# LPC54114_cm0plus register map
Vendor: nxp.com; File version: 1.0
CPU: CM0PLUS r0p0, little endian, no MPU, no FPU, VTOR, 2 interrupt priority bits
Registers are 32-bit, read-write, reset 0x0 unless marked. A register's access mark holds for its fields unless they carry their own. Offsets are from the block's base; [hi:lo] are bit positions; {n}, {i} and the like mark numbered series; 'fields as' and 'values as' point back to an identical list.

## IOCON — LPC5411x I/O pin configuration (IOCON)
Base 0x40001000
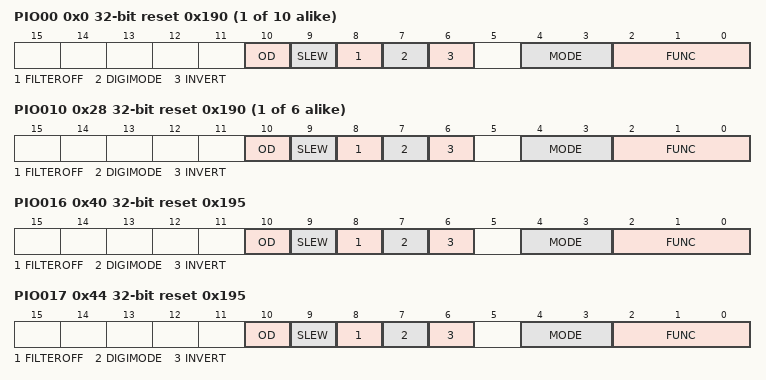
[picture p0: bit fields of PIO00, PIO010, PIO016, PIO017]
{0x0+4i} PIO{i:02} reset 0x190 (i=0..9) — Digital I/O control for port 0 pins PIO0_{i}
  [10] OD — Controls open-drain mode.
    0=NORMAL (Normal. Normal push-pull output); 1=OPEN_DRAIN (Open-drain. Simulated open-drain output (high drive disabled).)
  [9] SLEW — Driver slew rate.
    0=STANDARD (Standard mode, output slew rate control is enabled. More outputs can be switched simultaneously.); 1=FAST (Fast mode, slew rate control is disabled. Refer to the appropriate specific device data sheet for details.)
  [8] FILTEROFF — Controls input glitch filter.
    0=ENABLED (Filter enabled. Noise pulses below approximately 10 ns are filtered out.); 1=DISABLED (Filter disabled. No input filtering is done.)
  [7] DIGIMODE — Select Analog/Digital mode.
    0=ANALOG (Analog mode.); 1=DIGITAL (Digital mode.)
  [6] INVERT — Input polarity.
    0=DISABLED (Disabled. Input function is not inverted.); 1=ENABLED (Enabled. Input is function inverted.)
  [4:3] MODE — Selects function mode (on-chip pull-up/pull-down resistor control).
    0=INACTIVE (Inactive. Inactive (no pull-down/pull-up resistor enabled).); 1=PULL_DOWN (Pull-down. Pull-down resistor enabled.); 2=PULL_UP (Pull-up. Pull-up resistor enabled.); 3=REPEATER (Repeater. Repeater mode.)
  [2:0] FUNC — Selects pin function.
    {v}=ALT{v} (Alternative connection {v}.) (v=0..7)
{0x0+4i} PIO{i:03} reset 0x190 (i=10..15) — Digital I/O control for port 0 pins PIO0_{i}
  fields as PIO00
0x40 PIO016 reset 0x195 — Digital I/O control for port 0 pins PIO0_16
  fields as PIO00
0x44 PIO017 reset 0x195 — Digital I/O control for port 0 pins PIO0_17
  fields as PIO00
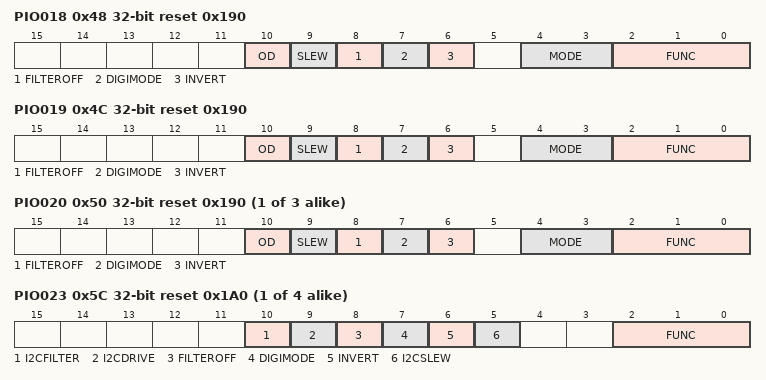
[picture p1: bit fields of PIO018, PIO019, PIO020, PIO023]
0x48 PIO018 reset 0x190 — Digital I/O control for port 0 pins PIO0_18
  fields as PIO00
0x4C PIO019 reset 0x190 — Digital I/O control for port 0 pins PIO0_19
  fields as PIO00
{0x0+4i} PIO{i:03} reset 0x190 (i=20..22) — Digital I/O control for port 0 pins PIO0_{i}
  fields as PIO00
{0x0+4i} PIO{i:03} reset 0x1A0 (i=23..26) — Digital I/O control for port 0 pins PIO0_{i}
  [10] I2CFILTER — Configures I2C features for standard mode, fast mode, and Fast Mode Plus operation.
    0=ENABLED (Enabled. I2C 50 ns glitch filter enabled.); 1=DISABLED (Disabled. I2C 50 ns glitch filter disabled.)
  [9] I2CDRIVE — Controls the current sink capability of the pin.
    0=LOW (Low drive. Output drive sink is 4 mA. This is sufficient for standard and fast mode I2C.); 1=HIGH (High drive. Output drive sink is 20 mA. This is needed for Fast Mode Plus I 2C. Refer to the appropriate specific device data sheet for details.)
  [8] FILTEROFF — Controls input glitch filter.
    values as PIO00.FILTEROFF
  [7] DIGIMODE — Select Analog/Digital mode.
    0=ANALOG (Analog mode.); 1=DIGITAL (Digital mode.)
  [6] INVERT — Input polarity.
    values as PIO00.INVERT
  [5] I2CSLEW — Controls slew rate of I2C pad.
    0=I2C_MODE; 1=GPIO_MODE
  [2:0] FUNC — Selects pin function.
    {v}=ALT{v} (Alternative connection {v}.) (v=0..7)
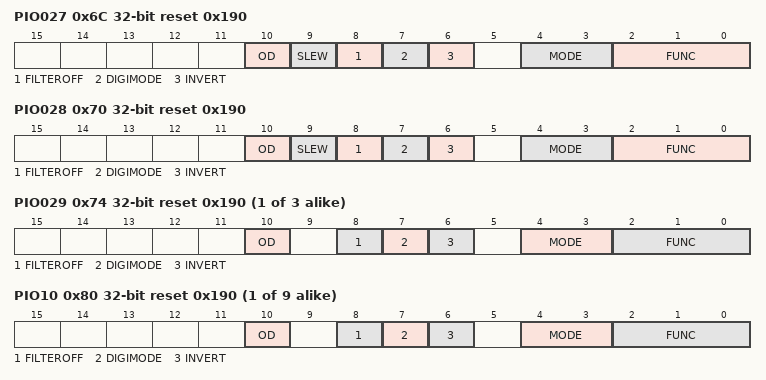
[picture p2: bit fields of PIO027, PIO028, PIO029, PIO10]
0x6C PIO027 reset 0x190 — Digital I/O control for port 0 pins PIO0_27
  fields as PIO00
0x70 PIO028 reset 0x190 — Digital I/O control for port 0 pins PIO0_28
  fields as PIO00
{0x0+4i} PIO{i:03} reset 0x190 (i=29..31) — Digital I/O control for port 0 pins PIO0_{i}
  [10] OD — Controls open-drain mode.
    values as PIO00.OD
  [8] FILTEROFF — Controls input glitch filter.
    values as PIO00.FILTEROFF
  [7] DIGIMODE — Select Analog/Digital mode.
    0=ANALOG (Analog mode.); 1=DIGITAL (Digital mode.)
  [6] INVERT — Input polarity.
    values as PIO00.INVERT
  [4:3] MODE — Selects function mode (on-chip pull-up/pull-down resistor control).
    values as PIO00.MODE
  [2:0] FUNC — Selects pin function.
    {v}=ALT{v} (Alternative connection {v}.) (v=0..7)
{0x58+4i} PIO{i} reset 0x190 (i=10..18) — Digital I/O control for port 1 pins PIO1_{i-10}
  fields as PIO029
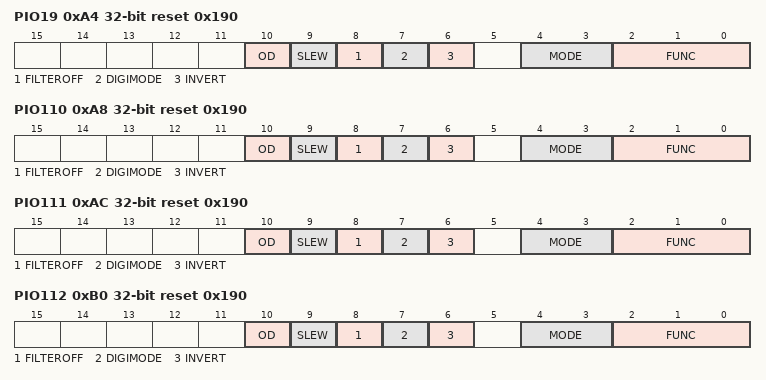
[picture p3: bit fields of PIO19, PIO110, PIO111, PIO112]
0xA4 PIO19 reset 0x190 — Digital I/O control for port 1 pins PIO1_9
  fields as PIO00
0xA8 PIO110 reset 0x190 — Digital I/O control for port 1 pins PIO1_10
  fields as PIO00
0xAC PIO111 reset 0x190 — Digital I/O control for port 1 pins PIO1_11
  fields as PIO00
0xB0 PIO112 reset 0x190 — Digital I/O control for port 1 pins PIO1_12
  fields as PIO00
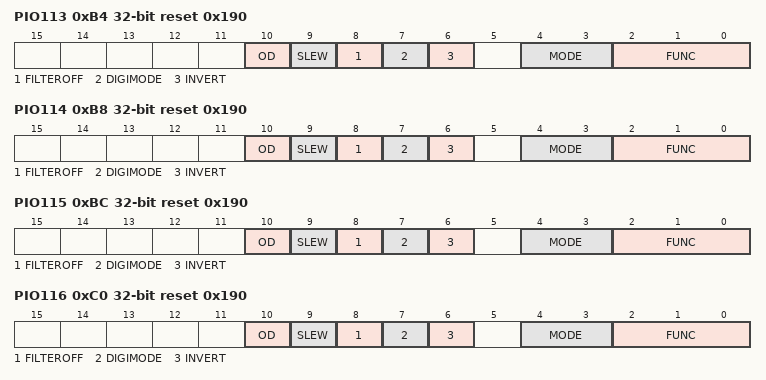
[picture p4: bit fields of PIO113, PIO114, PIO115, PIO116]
0xB4 PIO113 reset 0x190 — Digital I/O control for port 1 pins PIO1_13
  fields as PIO00
0xB8 PIO114 reset 0x190 — Digital I/O control for port 1 pins PIO1_14
  fields as PIO00
0xBC PIO115 reset 0x190 — Digital I/O control for port 1 pins PIO1_15
  fields as PIO00
0xC0 PIO116 reset 0x190 — Digital I/O control for port 1 pins PIO1_16
  fields as PIO00
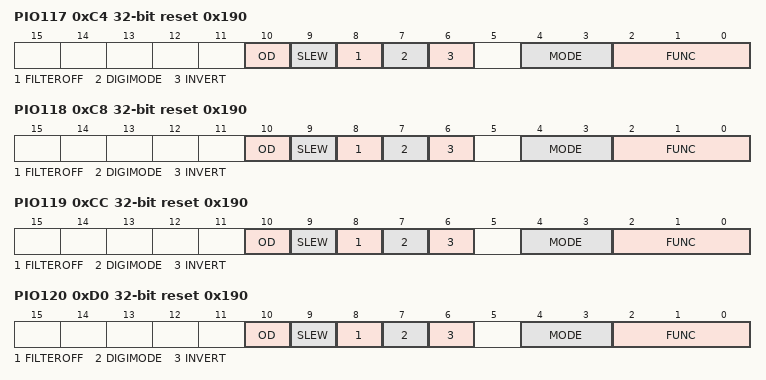
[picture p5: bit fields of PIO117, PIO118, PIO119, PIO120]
0xC4 PIO117 reset 0x190 — Digital I/O control for port 1 pins PIO1_17
  fields as PIO00
0xC8 PIO118 reset 0x190 — Digital I/O control for port 1 pins PIO1_18
  fields as PIO00
0xCC PIO119 reset 0x190 — Digital I/O control for port 1 pins PIO1_19
  fields as PIO00
0xD0 PIO120 reset 0x190 — Digital I/O control for port 1 pins PIO1_20
  fields as PIO00
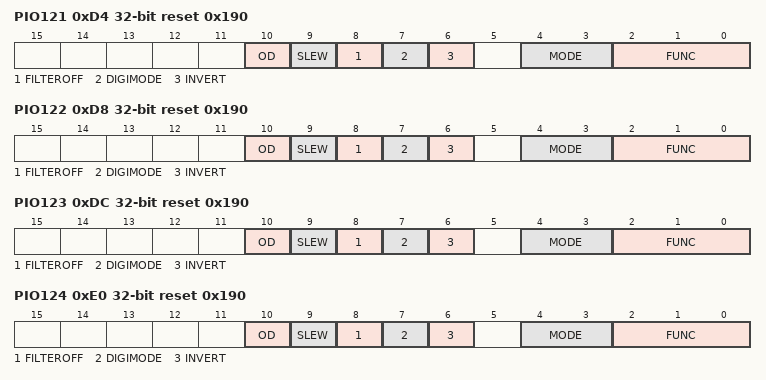
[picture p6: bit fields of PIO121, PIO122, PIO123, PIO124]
0xD4 PIO121 reset 0x190 — Digital I/O control for port 1 pins PIO1_21
  fields as PIO00
0xD8 PIO122 reset 0x190 — Digital I/O control for port 1 pins PIO1_22
  fields as PIO00
0xDC PIO123 reset 0x190 — Digital I/O control for port 1 pins PIO1_23
  fields as PIO00
0xE0 PIO124 reset 0x190 — Digital I/O control for port 1 pins PIO1_24
  fields as PIO00
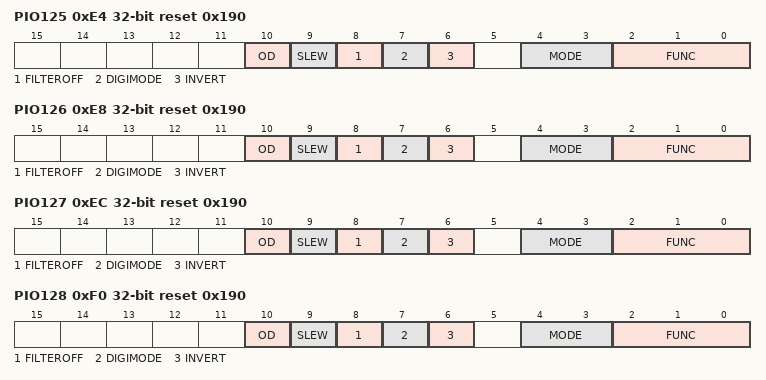
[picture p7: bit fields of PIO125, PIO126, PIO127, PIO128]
0xE4 PIO125 reset 0x190 — Digital I/O control for port 1 pins PIO1_25
  fields as PIO00
0xE8 PIO126 reset 0x190 — Digital I/O control for port 1 pins PIO1_26
  fields as PIO00
0xEC PIO127 reset 0x190 — Digital I/O control for port 1 pins PIO1_27
  fields as PIO00
0xF0 PIO128 reset 0x190 — Digital I/O control for port 1 pins PIO1_28
  fields as PIO00
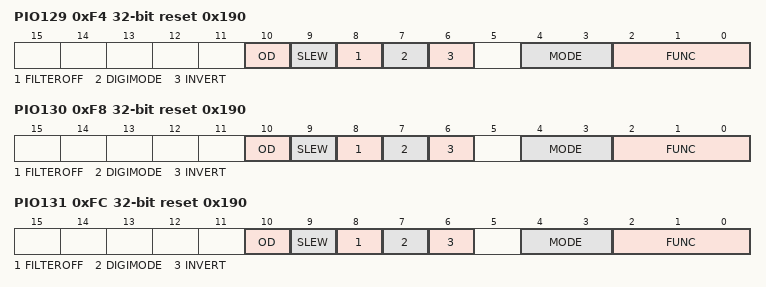
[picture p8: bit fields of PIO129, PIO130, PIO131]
0xF4 PIO129 reset 0x190 — Digital I/O control for port 1 pins PIO1_29
  fields as PIO00
0xF8 PIO130 reset 0x190 — Digital I/O control for port 1 pins PIO1_30
  fields as PIO00
0xFC PIO131 reset 0x190 — Digital I/O control for port 1 pins PIO1_31
  fields as PIO00
